# STM32H7S3xx register map
File version: 1.0
Registers are 32-bit, read-write, reset 0x0 unless marked. A register's access mark holds for its fields unless they carry their own. Offsets are from the block's base; [hi:lo] are bit positions; {n}, {i} and the like mark numbered series.

## HASH
Base 0x48020400
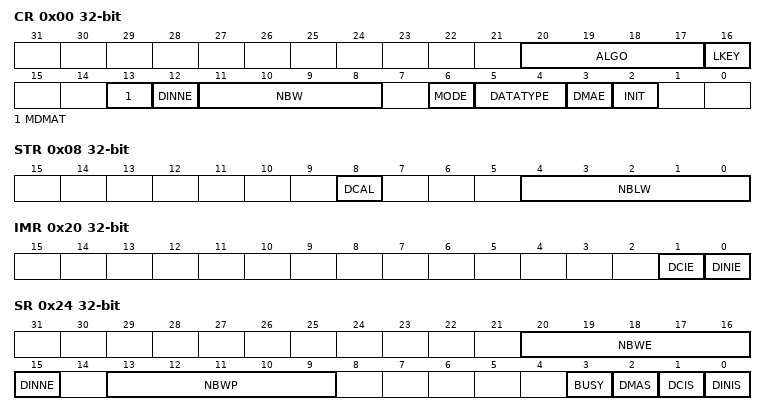
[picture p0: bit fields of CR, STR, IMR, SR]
0x00 CR — HASH control register
  [20:17] ALGO, [16] LKEY, [13] MDMAT, [12] DINNE, [11:8] NBW, [6] MODE, [5:4] DATATYPE, [3] DMAE, [2] INIT
0x04 DIN — HASH data input register
0x08 STR — HASH start register
  [8] DCAL, [4:0] NBLW
{0xC+4i} HR{i} (i=0..4) — HASH digest registers
0x20 IMR — HASH interrupt enable register
  [1] DCIE, [0] DINIE
0x24 SR — HASH status register
  [20:16] NBWE, [15] DINNE, [13:9] NBWP, [3] BUSY, [2] DMAS, [1] DCIS, [0] DINIS
{0xF8+4i} CSR[{i}] (i=0..102)
{0x310+4i} DIGEST_HR{i} (i=0..15) — HASH digest registers

## CRYP — Cryp Processor
Base 0x48020800
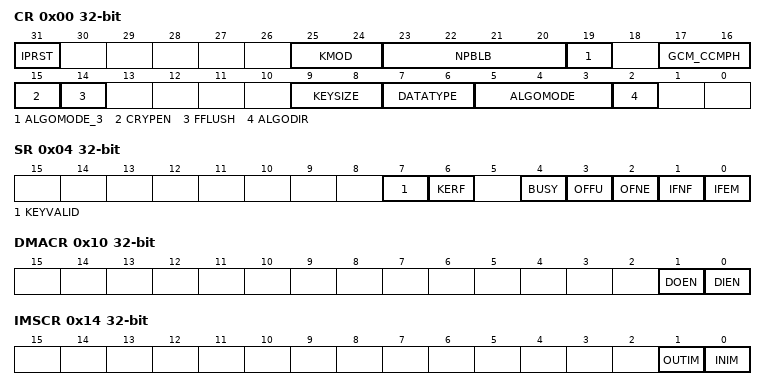
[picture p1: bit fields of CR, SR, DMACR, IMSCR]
0x00 CR — CRYP control register
  [31] IPRST — CRYP peripheral software reset
  [25:24] KMOD — Key mode selection
  [23:20] NPBLB — Number of Padding Bytes in Last Block of payload
  [19] ALGOMODE_3 — Algorithm mode
  [17:16] GCM_CCMPH — GCM or CCM Phase selection
  [15] CRYPEN — CRYP processor enable
  [14] FFLUSH — CRYP FIFO Flush
  [9:8] KEYSIZE — Key Size selection
  [7:6] DATATYPE — Data Type selection
  [5:3] ALGOMODE — Algorithm mode
  [2] ALGODIR — Algorithm direction (Encrypt/Decrypt)
0x04 SR — CRYP status register
  [7] KEYVALID — Key valid flag
  [6] KERF — Key error flag
  [4] BUSY — Busy bit
  [3] OFFU — Output FIFO full flag
  [2] OFNE — Output FIFO not empty flag
  [1] IFNF — Input FIFO not full flag
  [0] IFEM — Input FIFO empty flag
0x08 DIN — CRYP data input register
  [31:0] DATAIN — CRYP Data Input
0x0C DOUT — CRYP data output register
  [31:0] DATAOUT — CRYP Data Output
0x10 DMACR — CRYP DMA control register
  [1] DOEN — DMA Output Enable
  [0] DIEN — DMA Input Enable
0x14 IMSCR — CRYP interrupt mask set/clear register
  [1] OUTIM — Output FIFO service interrupt mask
  [0] INIM — Input FIFO service interrupt mask
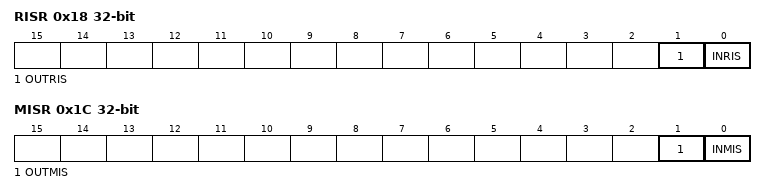
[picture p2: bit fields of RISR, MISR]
0x18 RISR — CRYP raw interrupt status register
  [1] OUTRIS — Output FIFO service raw interrupt mask
  [0] INRIS — Input FIFO service raw interrupt status
0x1C MISR — CRYP masked interrupt status register
  [1] OUTMIS — Output FIFO service masked interrupt status
  [0] INMIS — Input FIFO service masked interrupt status
0x20 K0LR — CRYP key left register 0
  [31:0] K — AES key bit x (x= 224 to 255)
0x24 K0RR — CRYP key right register 0
  [31:0] K — AES key bit x (x= 192 to 223)
0x28 K1LR — CRYP key left register 1
  [31:0] K1LR — AES key bit x (x= 160 to 291)
0x2C K1RR — CRYP key right register 1
  [31:0] K1RR — AES key bit x (x= 128 to 159)
0x30 K2LR — CRYP key left register 2
  [31:0] K — AES key bit x (x= 96 to 127)
0x34 K2RR — CRYP key right register 2
  [31:0] K — AES key bit x (x= 64 to 95)
0x38 K3LR — CRYP key left register 3
  [31:0] K — AES key bit x (x= 32 to 63)
0x3C K3RR — CRYP key right register 3
  [31:0] K — AES key bit x (x= 0 to 31)
0x40 IV0LR — CRYP initialization vector left-word register 0
  [31:0] IV — Initialization vector bit x (x= 0 to 31)
0x44 IV0RR — CRYP initialization vector right-word register 0
  [31:0] IV — Initialization vector bit x (x= 32 to 63)
0x48 IV1LR — CRYP initialization vector left-word register 1
  [31:0] IV — Initialization vector bit x (x= 64 to 95)
0x4C IV1RR — CRYP initialization vector right-word register 1
  [31:0] IV — Initialization vector bit x (x= 96 to 127)
{0x50+4i} CSGCMCCM{i}R (i=0..7) — CRYP GCM/GMAC or CCM/CMAC context swap register {i}
  [31:0] CSGCMCCM{i} — CRYP internal state registers for GCM, GMAC and CCM modes
{0x70+4i} CSGCM{i}R (i=0..7) — CRYP GCM/GMAC context swap register {i}
  [31:0] CSGCM{i} — CRYP internal state registers for GCM and GMAC modes

## SAES — SAES Processor
Base 0x48021000
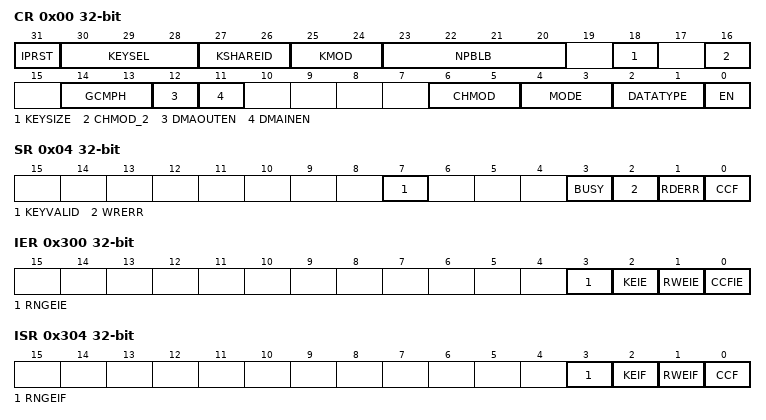
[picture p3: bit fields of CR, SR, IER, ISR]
0x00 CR — SAES control register
  [31] IPRST — SAES IP software reset
  [30:28] KEYSEL — Key Selection
  [27:26] KSHAREID — Key Shared ID
  [25:24] KMOD — Key mode selection
  [23:20] NPBLB — Number of padding bytes in payload last block
  [18] KEYSIZE — Key size selection
  [16] CHMOD_2 — SAES Chaining Mode
  [14:13] GCMPH — GCM Phase
  [12] DMAOUTEN — Enable data output phase DMA management
  [11] DMAINEN — Enable data input phase DMA management
  [6:5] CHMOD — SAES Chaining Mode
  [4:3] MODE — SAES Mode Of Operation
  [2:1] DATATYPE — Data type selection
  [0] EN — SAES Enable
0x04 SR — SAES status register
  [7] KEYVALID — KEYVALID Flag
  [3] BUSY — Busy Flag
  [2] WRERR — Write Error Flag
  [1] RDERR — Read Error Flag
  [0] CCF — Computation Complete Flag
0x08 DINR — SAES data input register
  [31:0] DINR — SAES Data Input Register
0x0C DOUTR — SAES data output register
  [31:0] DOUTR — SAES Data Output Register
{0x10+4i} KEYR{i} (i=0..3) — SAES key register {i}
  [31:0] KEYR{i} — SAES Key Register {i}
{0x20+4i} IVR{i} (i=0..3) — SAES initialization vector register {i}
  [31:0] IVR{i} — SAES Initialization Vector Register {i}
{0x20+4i} KEYR{i} (i=4..7) — SAES key register {i}
  [31:0] KEYR{i} — SAES Key Register {i}
{0x40+4i} SUSP{i}R (i=0..4) — SAES Suspend register {i}
  [31:0] SUSP{i}R — SAES Suspend registers {i}
0x54 SUSP5R — SAES Suspend register 5
  [31:0] SUSP5R — AES Suspend registers 5
0x58 SUSP6R — SAES Suspend register 6
  [31:0] SUSP6R — SAES Suspend registers 6
0x5C SUSP7R — SAES Suspend register 7
  [31:0] SUSP7R — SAES Suspend registers 7
0x300 IER — SAES Interrupt Enable Register
  [3] RNGEIE — Rng error interrupt enable
  [2] KEIE — Key error interrupt enable
  [1] RWEIE — Read or write error Interrupt Enable
  [0] CCFIE — Computation complete flag interrupt enable
0x304 ISR — SAES Interrupt Status Register
  [3] RNGEIF — Rng error interrupt flag
  [2] KEIF — Key error interrupt flag
  [1] RWEIF — Read or write error Interrupt flag
  [0] CCF — Computation complete flag
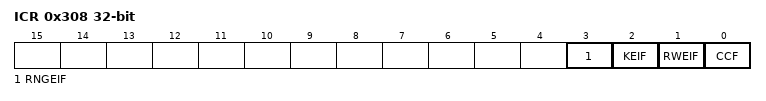
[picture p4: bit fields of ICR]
0x308 ICR — SAES Interrupt Clear Register
  [3] RNGEIF — Rng error interrupt flag clear
  [2] KEIF — Key error interrupt flag clear
  [1] RWEIF — Read or write error Interrupt flag clear
  [0] CCF — Computation complete flag clear
